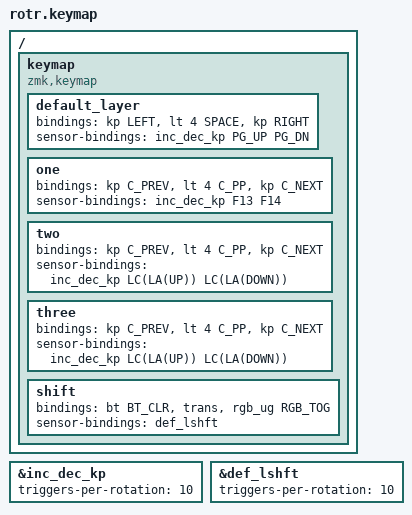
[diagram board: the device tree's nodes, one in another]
#include <behaviors.dtsi>
#include <dt-bindings/zmk/keys.h>
#include <dt-bindings/zmk/rgb.h>
#include <dt-bindings/zmk/bt.h>

&inc_dec_kp {
	triggers-per-rotation = <10>;
};
&def_lshft {
	triggers-per-rotation = <10>;
};

/ {
	keymap {
		compatible = "zmk,keymap";

		default_layer {
			//PREV | PLAY/PAUSE | NEXT
			bindings = <&kp LEFT &lt 4 SPACE &kp RIGHT>;
			sensor-bindings = <&inc_dec_kp PG_UP PG_DN>;
		};
		
		one {
  		  //Spotify PREV | PLAY/PAUSE | NEXT
  		  bindings = <&kp C_PREV &lt 4 C_PP &kp C_NEXT>;
  		  sensor-bindings = <&inc_dec_kp F13 F14>; 
		};


		two {
			//Media PREV | PLAY/PAUSE | NEXT
			bindings = <&kp C_PREV &lt 4 C_PP &kp C_NEXT>;
			sensor-bindings = <&inc_dec_kp LC(LA(UP)) LC(LA(DOWN))>;
		};
		three {
			//Media PREV | PLAY/PAUSE | NEXT
			bindings = <&kp C_PREV &lt 4 C_PP &kp C_NEXT>;
			sensor-bindings = <&inc_dec_kp LC(LA(UP)) LC(LA(DOWN))>;
		};
		shift {
			//PREV | PLAY/PAUSE | NEXT
			bindings = <&bt BT_CLR &trans &rgb_ug RGB_TOG>;
			sensor-bindings = <&def_lshft>;
		};
	};
};
